# EC register map
Vendor: litex
Betrusted EC
Registers are 32-bit, read-write, reset 0x0 unless marked. A register's access mark holds for its fields unless they carry their own. Offsets are from the block's base; lines under a group give offsets from that group; [hi:lo] are bit positions; {n}, {i} and the like mark numbered series; 'fields as' and 'values as' point back to an identical list; <NAME> marks a mode.

## Memory map
0xE0000000 CTRL size 0xC
0xE0001000 TIMER0 size 0x20
0xE0001800 CRG size 0x4
0xE0002000 GIT size 0x8
0xE0002800 POWER size 0x8
0xE0003000 UART_PHY size 0x4
0xE0003800 UART size 0x20
0xE0004000 PICORVSPI size 0xC
0xE0004800 I2C size 0x30
0xE0005000 TICKTIMER size 0x20
0xE0005800 COM size 0x8
0xE0006000 WIFI size 0x24

## Interrupts
0 timer0 (TIMER0)
1 uart (UART)
2 i2c (I2C)
3 ticktimer (TICKTIMER)
4 wifi (WIFI)

## Further device data
memoryRegions:
  SRAM baseAddress=0x10000000 size=0x00020000
  SPIFLASH baseAddress=0x20000000 size=0x00100000
  COM baseAddress=0xD0000000 size=0x00000004
  CSR baseAddress=0xE0000000 size=0x00010000

## CTRL
Base 0xE0000000
0x00 RESET — Write a ``1`` to this register to reset the SoC.
  [0] reset
0x04 SCRATCH reset 0x12345678 — Use this register as a scratch space to verify that software read/write accesses to the Wishbone/CSR bus are working correctly. The initial reset value of 0x1234578 can be used to verify endianness.
0x08 BUS_ERRORS — Total number of Wishbone bus errors (timeouts) since start.

## TIMER0
Base 0xE0001000
0x00 LOAD — Load value when Timer is (re-)enabled. In One-Shot mode, the value written to this register specifies the Timer's duration in clock cycles.
0x04 RELOAD — Reload value when Timer reaches ``0``. In Periodic mode, the value written to this register specify the Timer's period in clock cycles.
0x08 EN — Enable flag of the Timer. Set this flag to ``1`` to enable/start the Timer. Set to ``0`` to disable the Timer.
  [0] en
0x0C UPDATE_VALUE — Update trigger for the current countdown value. A write to this register latches the current countdown value to ``value`` register.
  [0] update_value
0x10 VALUE — Latched countdown value. This value is updated by writing to ``update_value``.
0x14 EV_STATUS — This register contains the current raw level of the zero event trigger. Writes to this register have no effect.
  [0] zero — Level of the ``zero`` event
0x18 EV_PENDING — When a zero event occurs, the corresponding bit will be set in this register. To clear the Event, set the corresponding bit in this register.
  [0] zero — `1` if a `zero` event occurred. This Event is triggered on a **falling** edge.
0x1C EV_ENABLE — This register enables the corresponding zero events. Write a ``0`` to this register to disable individual events.
  [0] zero — Write a ``1`` to enable the ``zero`` Event

## CRG
Base 0xE0001800
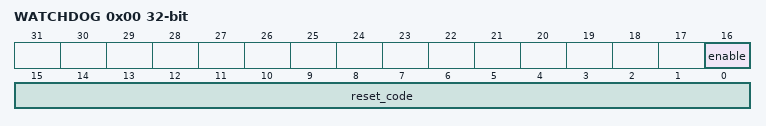
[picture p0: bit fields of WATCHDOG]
0x00 WATCHDOG
  [16] enable — Enable the watchdog timer. Cannot be disabled once enabled, except with a reset. Notably, a watchdog reset will disable the watchdog.
  [15:0] reset_code — Write `600d` then `c0de` in sequence to this register to reset the watchdog timer

## GIT
Base 0xE0002000
0x00 GITREV reset 0xB565873D — First 32-bits of the git revision. This documentation was built from git rev ``b565873d``, so this value is 3043329853, which should be enough to check out the exact git version used to build this firmware.
0x04 DIRTY reset 0x1
  [0] dirty — Set to ``1`` if this device was built from a git repo with uncommitted modifications.

## POWER
Base 0xE0002800
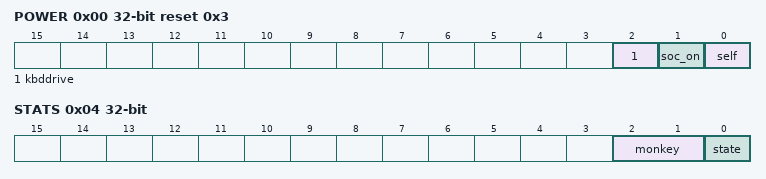
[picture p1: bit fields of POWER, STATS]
0x00 POWER reset 0x3
  [2] kbddrive — Writing `1` to this drives the scan column to 1. Do this prior to reading to mitigate noise
  [1] soc_on — Writing `1` to this powers on the SoC
  [0] self — Writing `1` to this keeps the EC powered on
0x04 STATS
  [2:1] monkey — Power-on key monitor input
  [0] state — Current power state of the SOC

## UART_PHY
Base 0xE0003000
0x00 TUNING_WORD reset 0x1A36E2E
